AUTOSAR XML (schema 4-1-3)
standard types defined: boolean, uint8
package /UAES/ASW/CompuMethods
  compu method CM_boolean: 0=FALSE, 1=TRUE
package /UAES/ASW/DataConstrs
  range DC_boolean: raw 0..1
  range DC_uint8: raw 0..255
package /UAES/ASW/DataTypeMappingSets
  data type mapping set DTMS_Lock_DiagEnbCnd
package /UAES/ASW/PortInterfaces
  4 x sender receiver interface:
    BattU_bVoltEnbPinDiag: invalidation-policy{data-element=BattU_bVoltEnbPinDiag/Val, handle-invalid=DONT-INVALIDATE}
      data Val: sw-calibration-access=READ-ONLY, type=boolean
    gCAN_u8UMM_UsageModeSt: invalidation-policy{data-element=gCAN_u8UMM_UsageModeSt/Val, handle-invalid=DONT-INVALIDATE}
      data Val: sw-calibration-access=READ-ONLY, type=uint8
    gLock_u8DiagEnbCnd: invalidation-policy{data-element=gLock_u8DiagEnbCnd/Val, handle-invalid=DONT-INVALIDATE}
      data Val: sw-calibration-access=READ-ONLY, type=uint8
    gPRM_u8VehicleTypeCfg: invalidation-policy{data-element=gPRM_u8VehicleTypeCfg/Val, handle-invalid=DONT-INVALIDATE}
      data Val: sw-calibration-access=READ-ONLY, type=uint8
package /UAES/ASW/SwComponentTypes
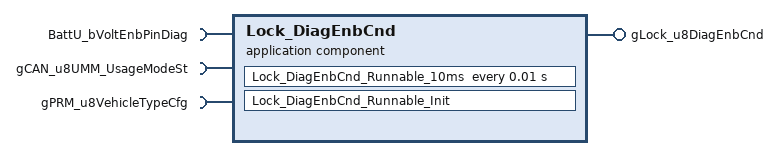
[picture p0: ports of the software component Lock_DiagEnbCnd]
  application sw component type Lock_DiagEnbCnd
    provide port gLock_u8DiagEnbCnd: nonqueued-sender-com-spec{data-element=gLock_u8DiagEnbCnd/Val, init-value=0}, provided-interface=gLock_u8DiagEnbCnd
    require port BattU_bVoltEnbPinDiag: nonqueued-receiver-com-spec{data-element=BattU_bVoltEnbPinDiag/Val, filter=data-filter-type=ALWAYS, init-value=0}, required-interface=BattU_bVoltEnbPinDiag
    require port gCAN_u8UMM_UsageModeSt: nonqueued-receiver-com-spec{data-element=gCAN_u8UMM_UsageModeSt/Val, filter=data-filter-type=ALWAYS, init-value=0}, required-interface=gCAN_u8UMM_UsageModeSt
    require port gPRM_u8VehicleTypeCfg: nonqueued-receiver-com-spec{data-element=gPRM_u8VehicleTypeCfg/Val, filter=data-filter-type=ALWAYS, init-value=0}, required-interface=gPRM_u8VehicleTypeCfg
    behavior Lock_DiagEnbCnd_InternalBehavior: data-type-mapping=DTMS_Lock_DiagEnbCnd
      timing event TMT_Lock_DiagEnbCnd_Runnable_10ms: start-on-event=Lock_DiagEnbCnd_Runnable_10ms, period=0.01
      init event Lock_DiagEnbCnd_InitEvent: start-on-event=Lock_DiagEnbCnd_Runnable_Init
      runnable Lock_DiagEnbCnd_Runnable_10ms
        data-receive-point-by-arguments:
          access REC_BattU_flgVoltEnbPinDiag_Val: accessed-variable=BattU_bVoltEnbPinDiag.Val
          access REC_gCAN_u8UMM_UsageModeSt_Val: accessed-variable=gCAN_u8UMM_UsageModeSt.Val
          access REC_gPRM_u8VehicleTypeCfg_Val: accessed-variable=gPRM_u8VehicleTypeCfg.Val
        data-send-points:
          access SEND_gLock_u8DiagEnbCnd_Val: accessed-variable=gLock_u8DiagEnbCnd.Val
      runnable Lock_DiagEnbCnd_Runnable_Init
  swc implementation Lock_DiagEnbCnd_Implementation: behavior=Lock_DiagEnbCnd_InternalBehavior
    code-descriptors:
      code Default: artifact-descriptors=autosar-engineering-object={short-label=Default, category=SWSRC}
package /UAES/ASW/Units
  unit NoUnit: factor-si-to-unit=1, offset-si-to-unit=0
